# SF32LB56x register map
File version: 1.0
CPU: CM33 r0p1, little endian, MPU, FPU, 3 interrupt priority bits
Registers are 32-bit, read-write, reset 0x0 unless marked. A register's access mark holds for its fields unless they carry their own. Offsets are from the block's base; [hi:lo] are bit positions; {n}, {i} and the like mark numbered series; 'fields as' and 'values as' point back to an identical list.

## AUDCODEC_LP
Base 0x50018000
0x00 ID reset 0xC0DEC001
  [31:0] FUNC — function id
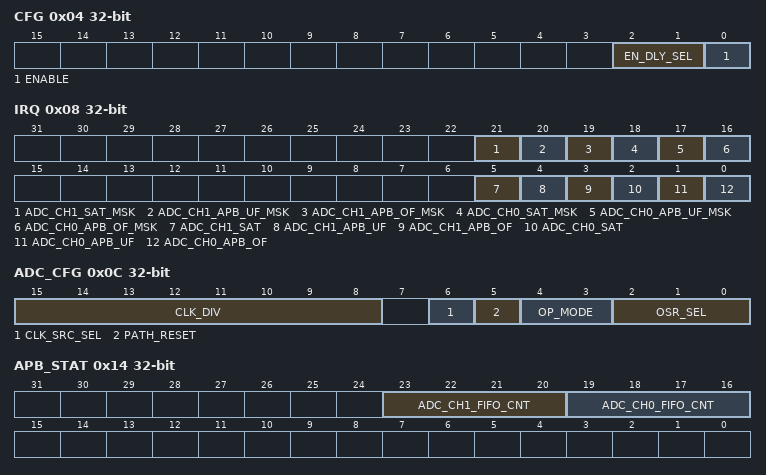
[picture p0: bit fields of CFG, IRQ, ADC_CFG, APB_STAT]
0x04 CFG
  [2:1] EN_DLY_SEL — codec enable delay count 0: no delay 1: 32 pclk 2: 64 pclk 3: 128 pclk
  [0] ENABLE — codec enable
0x08 IRQ
  [21] ADC_CH1_SAT_MSK — interrupt mask. 0: mask the interrupt.
  [20] ADC_CH1_APB_UF_MSK — interrupt mask. 0: mask the interrupt.
  [19] ADC_CH1_APB_OF_MSK — interrupt mask. 0: mask the interrupt.
  [18] ADC_CH0_SAT_MSK — interrupt mask. 0: mask the interrupt.
  [17] ADC_CH0_APB_UF_MSK — interrupt mask. 0: mask the interrupt.
  [16] ADC_CH0_APB_OF_MSK — interrupt mask. 0: mask the interrupt.
  [5] ADC_CH1_SAT — adc ch1 saturation interrupt
  [4] ADC_CH1_APB_UF — adc ch1 apb fifo underflow interrupt status. Write 1 to clear.
  [3] ADC_CH1_APB_OF — adc ch1 apb fifo overflow interrupt status. Write 1 to clear.
  [2] ADC_CH0_SAT — adc ch0 saturation interrupt
  [1] ADC_CH0_APB_UF — adc ch0 apb fifo underflow interrupt status. Write 1 to clear.
  [0] ADC_CH0_APB_OF — adc ch0 apb fifo overflow interrupt status. Write 1 to clear.
0x0C ADC_CFG
  [15:8] CLK_DIV — adc clock divider
  [6] CLK_SRC_SEL — adc clock source select 1: pll 0: xtal
  [5] PATH_RESET — adc path reset, set 1 to reset adc path
  [4:3] OP_MODE — adc operation mode 2'h0: normal mode: send adc data out through rx interface 2'h1: apb mode: send adc data out through apb interface 2'h2: raw data apb mode: send adc raw data out through apb interface 2'h3: reserved
  [2:0] OSR_SEL — ADC oversample rate 3'b000: 200 3'b001: 300 3'b010: 400 3'b011: 600 other: reserved
0x14 APB_STAT
  [23:20] ADC_CH1_FIFO_CNT, [19:16] ADC_CH0_FIFO_CNT
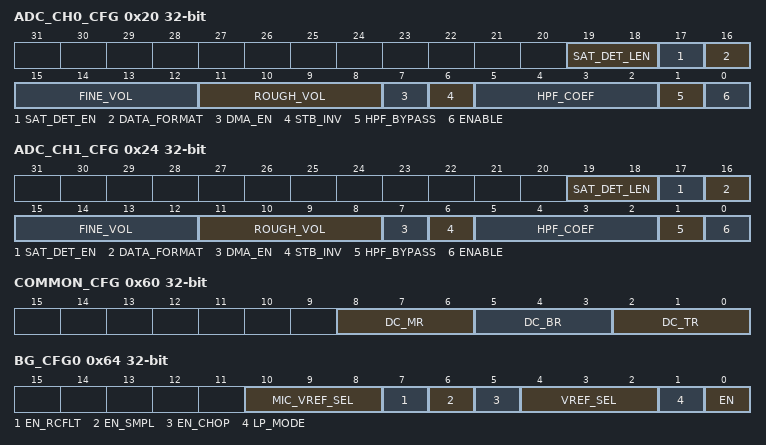
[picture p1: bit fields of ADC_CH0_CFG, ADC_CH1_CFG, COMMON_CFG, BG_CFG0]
0x20 ADC_CH0_CFG
  [19:18] SAT_DET_LEN — adc saturation detect pattern length 2'b00: 16 2'b01: 24 2'b10: 32 2'b11: 48
  [17] SAT_DET_EN — adc saturation detect
  [16] DATA_FORMAT — adc data format 1: 16-bit 0: 24-bit this bit only affect the data format accessed by apb interface. For 24-bit, every 24-bit data occupied 32-bit word. Bit[31:24] are zeros. For 16-bit mode, every 32-bit word contains two 16-bit audio data{D1, D0}
  [15:12] FINE_VOL — adc fine volume control range from 0dB to 6dB step is 0.5dB 4'h0: 0dB 4'h1: 0.5dB ...... 4'hb: 5.5dB 4'hc, 4'hd, 4'he, 4'hf: mute
  [11:8] ROUGH_VOL — adc rough volume control range from -60dB to 30dB step is 6dB 4'h0: -60dB 4'h1: -54dB ...... 4'ha: 0dB ...... 4'he: 24dB 4'hf: 30dB
  [7] DMA_EN — dma interface enable in apb mode and raw data apb mode 1: enable adc ch0 dma request interface 0: disable adc ch0 dma request interface
  [6] STB_INV — adc strobe inverter
  [5:2] HPF_COEF — high-pass filter coefficient
  [1] HPF_BYPASS — high-pass filter bypass
  [0] ENABLE — adc channel enable
0x24 ADC_CH1_CFG
  fields as ADC_CH0_CFG
0x40 ADC_CH0_ENTRY
  [31:0] DATA — adc channel0 data output
0x44 ADC_CH1_ENTRY
  [31:0] DATA — adc channel1 data output
0x60 COMMON_CFG
  [8:6] DC_MR — DC test Macro select
  [5:3] DC_BR — DC test Block select
  [2:0] DC_TR — DC test point select
0x64 BG_CFG0
  [10:8] MIC_VREF_SEL — select mic vref
  [7] EN_RCFLT — enable bandgap rc filter
  [6] EN_SMPL — enable bandgap sample
  [5] EN_CHOP — enable bandgap chop
  [4:2] VREF_SEL — set vref, 7: 2.8V
  [1] LP_MODE — 1: bandgap lp mode
  [0] EN — enable bandgap
0x68 BG_CFG1
  [31:0] SAMPCLK_HI — bg sample clock high cycle width, based on 0: stop bg sample clock
0x6C BG_CFG2
  [31:0] SAMPCLK_LO — bg sample clock low cycle width. 0: stop bg sample clock
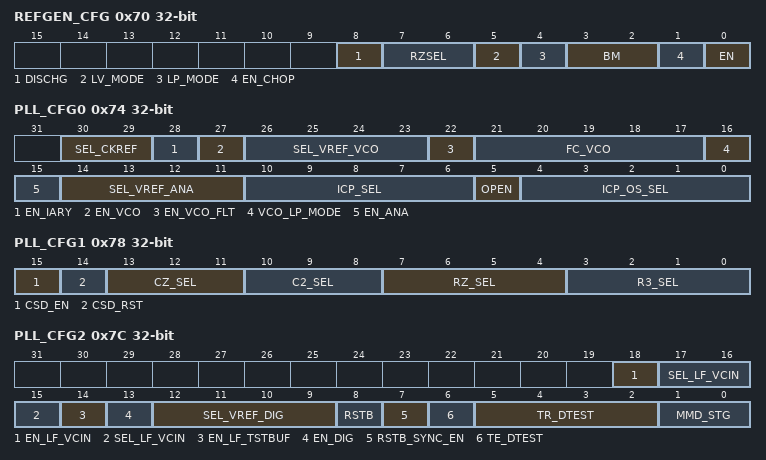
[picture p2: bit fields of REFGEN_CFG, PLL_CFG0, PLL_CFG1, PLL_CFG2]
0x70 REFGEN_CFG
  [8] DISCHG — discharge vref
  [7:6] RZSEL — sel Rz, 0: 1uF cap
  [5] LV_MODE — low vol mode
  [4] LP_MODE — 1: lpmode(adc), 0:dac
  [3:2] BM — bias mode
  [1] EN_CHOP — enable ref gen chop
  [0] EN — enable ref gen
0x74 PLL_CFG0
  [30:29] SEL_CKREF — select ref clock, 2: 24MHz
  [28] EN_IARY — enable I array
  [27] EN_VCO — enable vco
  [26:23] SEL_VREF_VCO — ldo vref, 7:1.1V
  [22] EN_VCO_FLT — vco bais filter
  [21:17] FC_VCO — VCO Fcode
  [16] VCO_LP_MODE — 1: lp mode
  [15] EN_ANA — enable ana block
  [14:11] SEL_VREF_ANA — ldo vref, 7:1.1V
  [10:6] ICP_SEL — select Icp, 1:1.25u
  [5] OPEN — 1: pll open
  [4:0] ICP_OS_SEL — Icp os
0x78 PLL_CFG1
  [15] CSD_EN — enable CSD
  [14] CSD_RST — reset CSD, high active
  [13:11] CZ_SEL — select Cz
  [10:8] C2_SEL — select C2
  [7:4] RZ_SEL — select Rz
  [3:0] R3_SEL — select R3
0x7C PLL_CFG2
  [18] EN_LF_VCIN — enable vcin for vco
  [17:15] SEL_LF_VCIN — select vcin, 4: 550mV
  [14] EN_LF_TSTBUF — enable vctrl buf
  [13] EN_DIG — enable dig block
  [12:9] SEL_VREF_DIG — ldo vref, 7:1.1V
  [8] RSTB — resetb
  [7] RSTB_SYNC_EN — resetb sync
  [6] TE_DTEST — enable dtest
  [5:2] TR_DTEST — select dtest
  [1:0] MMD_STG
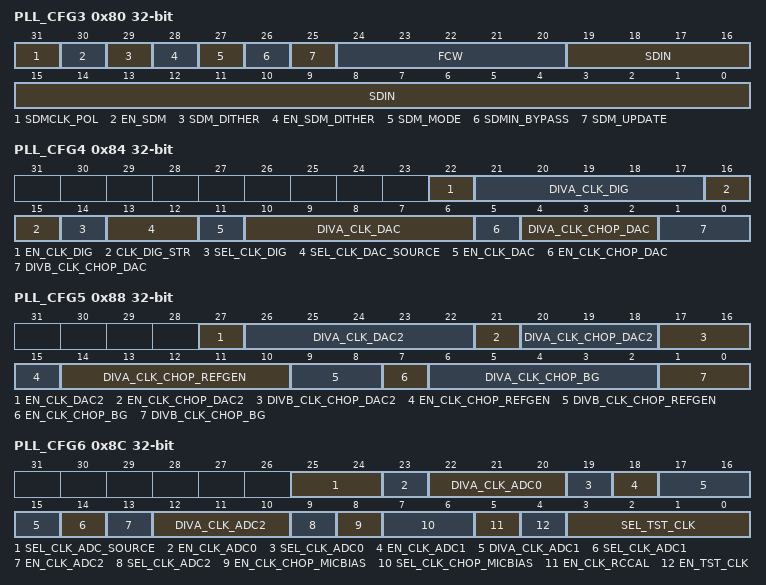
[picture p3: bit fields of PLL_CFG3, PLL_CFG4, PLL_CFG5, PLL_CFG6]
0x80 PLL_CFG3
  [31] SDMCLK_POL — sdm dig clk polarity
  [30] EN_SDM — enable sdm
  [29] SDM_DITHER
  [28] EN_SDM_DITHER — enable sdm dither
  [27] SDM_MODE
  [26] SDMIN_BYPASS — 1: bypass FCW and SDIN sdm control signal
  [25] SDM_UPDATE — write 1 to update FCW and SDIN value
  [24:20] FCW
  [19:0] SDIN — sdm input
0x84 PLL_CFG4
  [22] EN_CLK_DIG — enable dig clk
  [21:17] DIVA_CLK_DIG — DIVA dig clk
  [16:15] CLK_DIG_STR — strength
  [14] SEL_CLK_DIG — select dig clk 0: pll 1: 24MHz from xtal
  [13:12] SEL_CLK_DAC_SOURCE — 0: xtal 1: pll
  [11] EN_CLK_DAC — enable dac clk
  [10:6] DIVA_CLK_DAC — DIVA dac clk
  [5] EN_CLK_CHOP_DAC — enable dac chop clk
  [4:2] DIVA_CLK_CHOP_DAC — DIVA dac chop clk
  [1:0] DIVB_CLK_CHOP_DAC — DIVB dac chop clk
0x88 PLL_CFG5
  [27] EN_CLK_DAC2 — enable dac2 clk
  [26:22] DIVA_CLK_DAC2 — DIVA dac2 clk
  [21] EN_CLK_CHOP_DAC2 — enable dac2 chop clk
  [20:18] DIVA_CLK_CHOP_DAC2 — DIVA dac2 chop clk
  [17:16] DIVB_CLK_CHOP_DAC2 — DIVB dac2 chop clk
  [15] EN_CLK_CHOP_REFGEN — enable ref chop clk
  [14:10] DIVA_CLK_CHOP_REFGEN — DIVA ref chop clk
  [9:8] DIVB_CLK_CHOP_REFGEN — DIVB ref chop clk
  [7] EN_CLK_CHOP_BG — enable bg chop clk
  [6:2] DIVA_CLK_CHOP_BG — DIVA bg chop clk
  [1:0] DIVB_CLK_CHOP_BG — DIVB bg chop clk
0x8C PLL_CFG6
  [25:24] SEL_CLK_ADC_SOURCE — 0: xtal, 1: pll
  [23] EN_CLK_ADC0 — enable adc0 clk
  [22:20] DIVA_CLK_ADC0 — DIVA adc0 clk
  [19] SEL_CLK_ADC0 — select adc0 clk
  [18] EN_CLK_ADC1 — enable adc1 clk
  [17:15] DIVA_CLK_ADC1 — DIVA adc1 clk
  [14] SEL_CLK_ADC1 — select adc1 clk
  [13] EN_CLK_ADC2 — enable adc2 clk
  [12:10] DIVA_CLK_ADC2 — DIVA adc2 clk
  [9] SEL_CLK_ADC2 — select adc2 clk
  [8] EN_CLK_CHOP_MICBIAS — enable micbias chop clk
  [7:6] SEL_CLK_CHOP_MICBIAS — select micbias chop clk
  [5] EN_CLK_RCCAL — enable RC CAL clk
  [4] EN_TST_CLK — enable test clk
  [3:0] SEL_TST_CLK — select clk to test
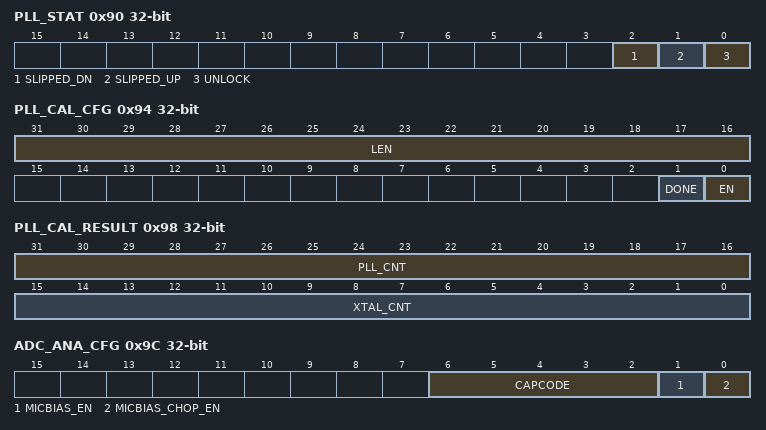
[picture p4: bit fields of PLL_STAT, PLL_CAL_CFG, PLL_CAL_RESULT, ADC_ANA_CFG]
0x90 PLL_STAT
  [2] SLIPPED_DN — slip dn
  [1] SLIPPED_UP — slip up
  [0] UNLOCK — 1:pll unlock
0x94 PLL_CAL_CFG
  [31:16] LEN — calibration length
  [1] DONE — calibration done
  [0] EN — calibration enable
0x98 PLL_CAL_RESULT
  [31:16] PLL_CNT — pll calibration counter result
  [15:0] XTAL_CNT — xtal calibration counter result
0x9C ADC_ANA_CFG
  [6:2] CAPCODE — ADC cap code
  [1] MICBIAS_EN — micbias enable
  [0] MICBIAS_CHOP_EN — micbias chopping enable
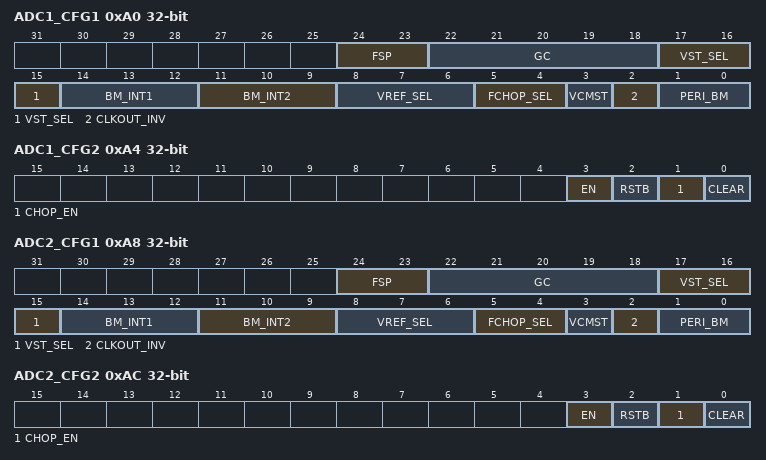
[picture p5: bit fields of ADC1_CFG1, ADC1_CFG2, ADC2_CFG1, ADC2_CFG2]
0xA0 ADC1_CFG1
  [24:23] FSP — sampling frequency: 0x0:9.6M 0x1:8.82M 0x2:4.8M 0x3:4.41M
  [22:18] GC — gaincode: 0x0:-10dB 0xa:0dB 0x1e:20dB
  [17:15] VST_SEL — start voltage 0x0:VCM+200mV 0x7:VCM+550mV
  [14:12] BM_INT1 — bias mode of first opamp
  [11:9] BM_INT2 — bias mode of 2nd and 3rd opamp
  [8:6] VREF_SEL — vref code from proper vcm in flash7 0x0:1.2V 0x1:1.4V 0x7:2.6V
  [5:4] FCHOP_SEL — chopping frequncy 0x0:÷8 0x1:÷16 0x2:÷32 0x3:÷64
  [3] VCMST — VCM quick settling
  [2] CLKOUT_INV — inverse output clock
  [1:0] PERI_BM — peripheral circuits biasmode
0xA4 ADC1_CFG2
  [3] EN — enable adc
  [2] RSTB — reset adc
  [1] CHOP_EN — chopping enable
  [0] CLEAR — clear adc
0xA8 ADC2_CFG1
  fields as ADC1_CFG1
0xAC ADC2_CFG2
  fields as ADC1_CFG2
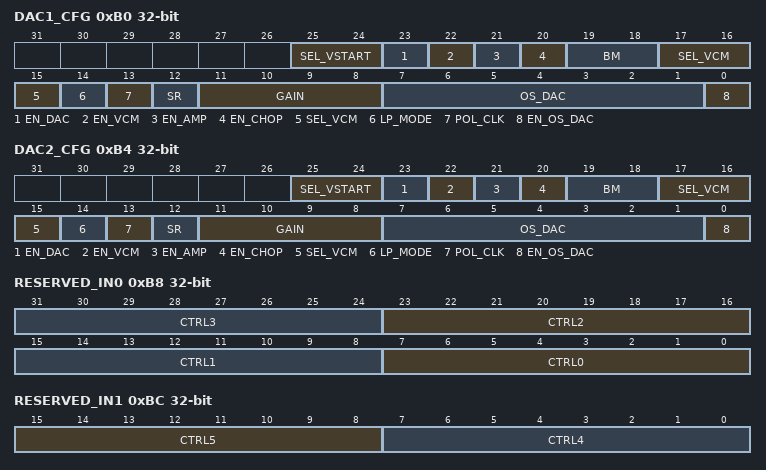
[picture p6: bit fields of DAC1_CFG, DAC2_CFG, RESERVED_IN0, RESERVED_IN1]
0xB0 DAC1_CFG
  [25:24] SEL_VSTART — select Vstart
  [23] EN_DAC — enable dac
  [22] EN_VCM — enable vcm
  [21] EN_AMP — enable amp
  [20] EN_CHOP — enable chop
  [19:18] BM — bias mode
  [17:15] SEL_VCM — select vcm
  [14] LP_MODE — 0: 3.3V sup, 1: 1.8V supply
  [13] POL_CLK — dac clk polarity
  [12] SR — dac short switch
  [11:8] GAIN — dac gain
  [7:1] OS_DAC
  [0] EN_OS_DAC — enable os dac
0xB4 DAC2_CFG
  fields as DAC1_CFG
0xB8 RESERVED_IN0
  [8n+7:8n] CTRL{n} (n=0..3) — reserved control {n}
0xBC RESERVED_IN1
  [15:8] CTRL5 — reserved control 5
  [7:0] CTRL4 — reserved control 4
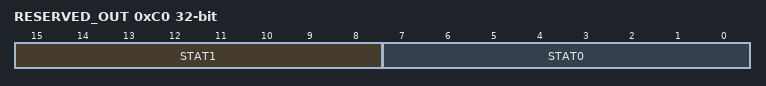
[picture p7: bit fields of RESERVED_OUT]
0xC0 RESERVED_OUT
  [15:8] STAT1 — reserved status1
  [7:0] STAT0 — reserved status0
